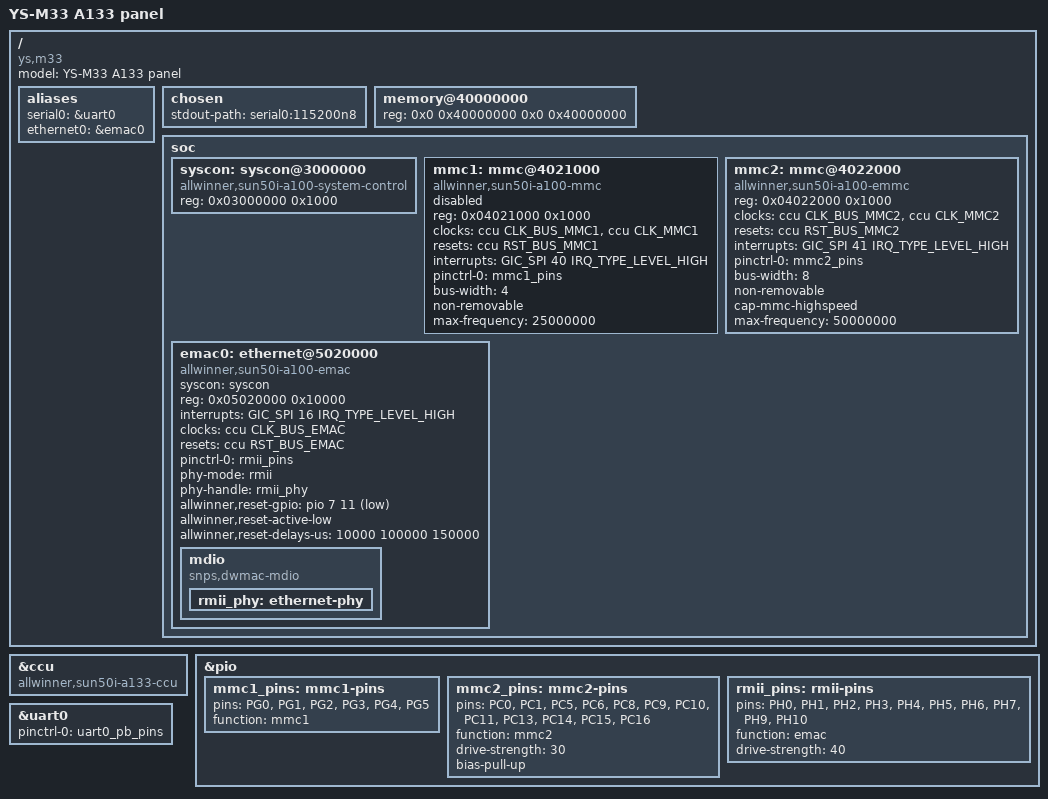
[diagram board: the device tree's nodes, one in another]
// SPDX-License-Identifier: (GPL-2.0-only OR MIT)
/*
 * YS-M33, the main board of a 10-inch wall panel with an Allwinner A133:
 * 1 GB of memory, 32 GB of eMMC, 100 Mbit/s Ethernet, an AXP803 power
 * management chip, a PCF8563 clock and an RTL8723DS wireless module.
 *
 * Addresses, interrupt numbers and pin functions are the ones the vendor
 * system of the board uses.
 */

/dts-v1/;

#include "sun50i-a100.dtsi"

#include <dt-bindings/gpio/gpio.h>

/* Local EmberBSD binding selects the A133 3-bit GPU divider explicitly. */
&ccu {
	compatible = "allwinner,sun50i-a133-ccu", "allwinner,sun50i-a100-ccu";
};

/ {
	model = "YS-M33 A133 panel";
	compatible = "ys,m33", "allwinner,sun50i-a133",
		     "allwinner,sun50i-a100";

	aliases {
		serial0 = &uart0;
		ethernet0 = &emac0;
	};

	chosen {
		stdout-path = "serial0:115200n8";
	};

	memory@40000000 {
		device_type = "memory";
		reg = <0x0 0x40000000 0x0 0x40000000>;
	};

	soc {
		syscon: syscon@3000000 {
			compatible = "allwinner,sun50i-a100-system-control",
				     "allwinner,sun50i-a64-system-control";
			reg = <0x03000000 0x1000>;
			#address-cells = <1>;
			#size-cells = <1>;
			ranges;
		};

		mmc1: mmc@4021000 {
			compatible = "allwinner,sun50i-a100-mmc";
			reg = <0x04021000 0x1000>;
			clocks = <&ccu CLK_BUS_MMC1>, <&ccu CLK_MMC1>;
			clock-names = "ahb", "mmc";
			resets = <&ccu RST_BUS_MMC1>;
			reset-names = "ahb";
			interrupts = <GIC_SPI 40 IRQ_TYPE_LEVEL_HIGH>;
			pinctrl-names = "default";
			pinctrl-0 = <&mmc1_pins>;
			bus-width = <4>;
			non-removable;
			max-frequency = <25000000>;
			/* Enable only with a verified board power profile. */
			status = "disabled";
			#address-cells = <1>;
			#size-cells = <0>;
		};

		mmc2: mmc@4022000 {
			compatible = "allwinner,sun50i-a100-emmc";
			reg = <0x04022000 0x1000>;
			clocks = <&ccu CLK_BUS_MMC2>, <&ccu CLK_MMC2>;
			clock-names = "ahb", "mmc";
			resets = <&ccu RST_BUS_MMC2>;
			reset-names = "ahb";
			interrupts = <GIC_SPI 41 IRQ_TYPE_LEVEL_HIGH>;
			pinctrl-names = "default";
			pinctrl-0 = <&mmc2_pins>;
			bus-width = <8>;
			non-removable;
			cap-mmc-highspeed;
			max-frequency = <50000000>;
			status = "okay";
			#address-cells = <1>;
			#size-cells = <0>;
		};

		emac0: ethernet@5020000 {
			compatible = "allwinner,sun50i-a100-emac",
				     "allwinner,sun50i-a64-emac";
			syscon = <&syscon>;
			reg = <0x05020000 0x10000>;
			interrupts = <GIC_SPI 16 IRQ_TYPE_LEVEL_HIGH>;
			interrupt-names = "macirq";
			clocks = <&ccu CLK_BUS_EMAC>;
			clock-names = "stmmaceth";
			resets = <&ccu RST_BUS_EMAC>;
			reset-names = "stmmaceth";
			pinctrl-names = "default";
			pinctrl-0 = <&rmii_pins>;
			phy-mode = "rmii";
			phy-handle = <&rmii_phy>;
			allwinner,reset-gpio = <&pio 7 11 GPIO_ACTIVE_LOW>; /* PH11 */
			allwinner,reset-active-low;
			allwinner,reset-delays-us = <10000 100000 150000>;
			status = "okay";

			mdio {
				compatible = "snps,dwmac-mdio";
				#address-cells = <1>;
				#size-cells = <0>;

				rmii_phy: ethernet-phy {
				};
			};
		};
	};
};

&pio {
	mmc1_pins: mmc1-pins {
		pins = "PG0", "PG1", "PG2", "PG3", "PG4", "PG5";
		function = "mmc1";
	};

	mmc2_pins: mmc2-pins {
		pins = "PC0", "PC1", "PC5", "PC6", "PC8", "PC9", "PC10",
		       "PC11", "PC13", "PC14", "PC15", "PC16";
		function = "mmc2";
		drive-strength = <30>;
		bias-pull-up;
	};

	rmii_pins: rmii-pins {
		pins = "PH0", "PH1", "PH2", "PH3", "PH4", "PH5", "PH6",
		       "PH7", "PH9", "PH10";
		function = "emac";
		drive-strength = <40>;
	};
};

&uart0 {
	pinctrl-names = "default";
	pinctrl-0 = <&uart0_pb_pins>;
	status = "okay";
};
